# PIC32MK0256GPG064 register map
Vendor: Microchip
Registers are 32-bit, read-write, reset 0x0 unless marked. A register's access mark holds for its fields unless they carry their own. Addresses are absolute, and some are shared; only a register's first bit layout is shown; [hi:lo] are bit positions.

## TMR8
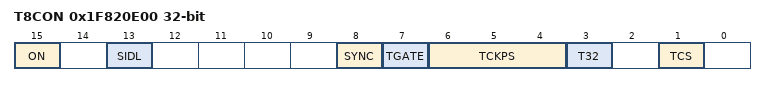
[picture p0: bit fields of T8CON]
0x1F820E00 T8CON reset not defined — Timer Configuration (power-on value ----------------000----x00000-0-)
  [15] ON — Timer On bit
    1=Module is enabled; 0=Module is disabled
  [13] SIDL — Stop in Idle Mode bit
    1=Discontinue operation when device enters Idle mode; 0=Continue operation even in Idle mode
  [8] SYNC — Synchronized Timer Start/Stop Enable bit
    1=Synchronized timer Start/Stop is enabled; 0=Synchronized timer Start/Stop is disabled
  [7] TGATE — Timer Gated Time Accumulation Enable bit
    1=Gated time accumulation is enabled; 0=Gated time accumulation is disabled
  [6:4] TCKPS — Timer Input Clock Prescale Select bits
    7=1:256 prescale value; 6=1:64 prescale value; 5=1:32 prescale value; 4=1:16 prescale value; 3=1:8 prescale value; 2=1:4 prescale value; 1=1:2 prescale value; 0=1:1 prescale value
  [3] T32 — 32-Bit Timer Mode Select bit
    1=32-bit Timer mode; 0=16-bit Timer mode
  [1] TCS — Timer Clock Source Select bit
    1=External clock from TxCK pin; 0=Internal peripheral clock
0x1F820E10 TMR8 — Timer
0x1F820E20 PR8 reset 0xFFFFFFFF — Timer Period

## TMR9
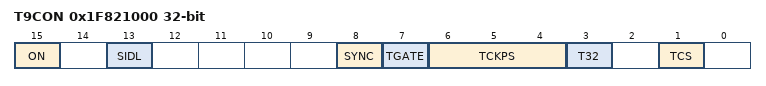
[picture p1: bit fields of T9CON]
0x1F821000 T9CON reset not defined — Timer Configuration (power-on value ----------------000----x00000-0-)
  [15] ON — Timer On bit
    1=Module is enabled; 0=Module is disabled
  [13] SIDL — Stop in Idle Mode bit
    1=Discontinue operation when device enters Idle mode; 0=Continue operation even in Idle mode
  [8] SYNC — Synchronized Timer Start/Stop Enable bit
    1=Synchronized timer Start/Stop is enabled; 0=Synchronized timer Start/Stop is disabled
  [7] TGATE — Timer Gated Time Accumulation Enable bit
    1=Gated time accumulation is enabled; 0=Gated time accumulation is disabled
  [6:4] TCKPS — Timer Input Clock Prescale Select bits
    7=1:256 prescale value; 6=1:64 prescale value; 5=1:32 prescale value; 4=1:16 prescale value; 3=1:8 prescale value; 2=1:4 prescale value; 1=1:2 prescale value; 0=1:1 prescale value
  [3] T32 — 32-Bit Timer Mode Select bit
    1=32-bit Timer mode; 0=16-bit Timer mode
  [1] TCS — Timer Clock Source Select bit
    1=External clock from TxCK pin; 0=Internal peripheral clock
0x1F821010 TMR9 — Timer
0x1F821020 PR9 reset 0xFFFFFFFF — Timer Period

## ICAP1
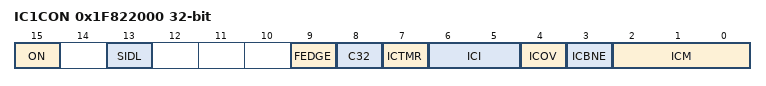
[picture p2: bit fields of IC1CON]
0x1F822000 IC1CON
  [15] ON, [13] SIDL, [9] FEDGE, [8] C32, [7] ICTMR, [6:5] ICI, [4] ICOV ro, [3] ICBNE ro, [2:0] ICM
0x1F822010 IC1BUF ro reset not defined — (power-on value xxxxxxxxxxxxxxxxxxxxxxxxxxxxxxxx)

## ICAP2
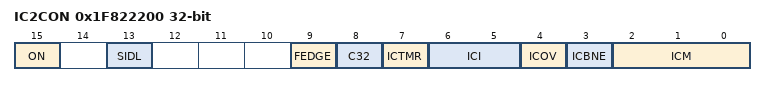
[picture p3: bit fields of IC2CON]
0x1F822200 IC2CON
  [15] ON, [13] SIDL, [9] FEDGE, [8] C32, [7] ICTMR, [6:5] ICI, [4] ICOV ro, [3] ICBNE ro, [2:0] ICM
0x1F822210 IC2BUF ro reset not defined — (power-on value xxxxxxxxxxxxxxxxxxxxxxxxxxxxxxxx)

## ICAP3
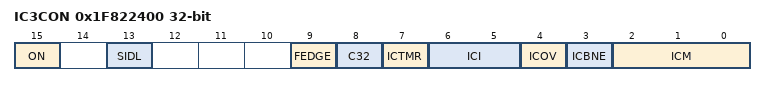
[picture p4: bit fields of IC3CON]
0x1F822400 IC3CON
  [15] ON, [13] SIDL, [9] FEDGE, [8] C32, [7] ICTMR, [6:5] ICI, [4] ICOV ro, [3] ICBNE ro, [2:0] ICM
0x1F822410 IC3BUF ro reset not defined — (power-on value xxxxxxxxxxxxxxxxxxxxxxxxxxxxxxxx)

## ICAP4
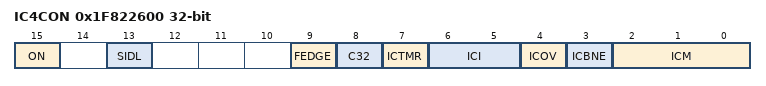
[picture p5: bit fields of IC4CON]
0x1F822600 IC4CON
  [15] ON, [13] SIDL, [9] FEDGE, [8] C32, [7] ICTMR, [6:5] ICI, [4] ICOV ro, [3] ICBNE ro, [2:0] ICM
0x1F822610 IC4BUF ro reset not defined — (power-on value xxxxxxxxxxxxxxxxxxxxxxxxxxxxxxxx)

## ICAP5
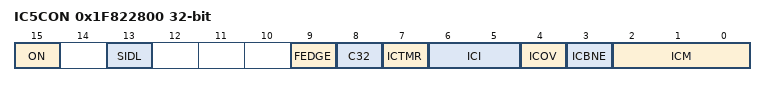
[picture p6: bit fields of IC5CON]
0x1F822800 IC5CON
  [15] ON, [13] SIDL, [9] FEDGE, [8] C32, [7] ICTMR, [6:5] ICI, [4] ICOV ro, [3] ICBNE ro, [2:0] ICM
0x1F822810 IC5BUF ro reset not defined — (power-on value xxxxxxxxxxxxxxxxxxxxxxxxxxxxxxxx)

## ICAP6
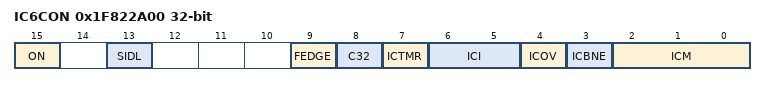
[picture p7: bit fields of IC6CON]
0x1F822A00 IC6CON
  [15] ON, [13] SIDL, [9] FEDGE, [8] C32, [7] ICTMR, [6:5] ICI, [4] ICOV ro, [3] ICBNE ro, [2:0] ICM
0x1F822A10 IC6BUF ro reset not defined — (power-on value xxxxxxxxxxxxxxxxxxxxxxxxxxxxxxxx)
